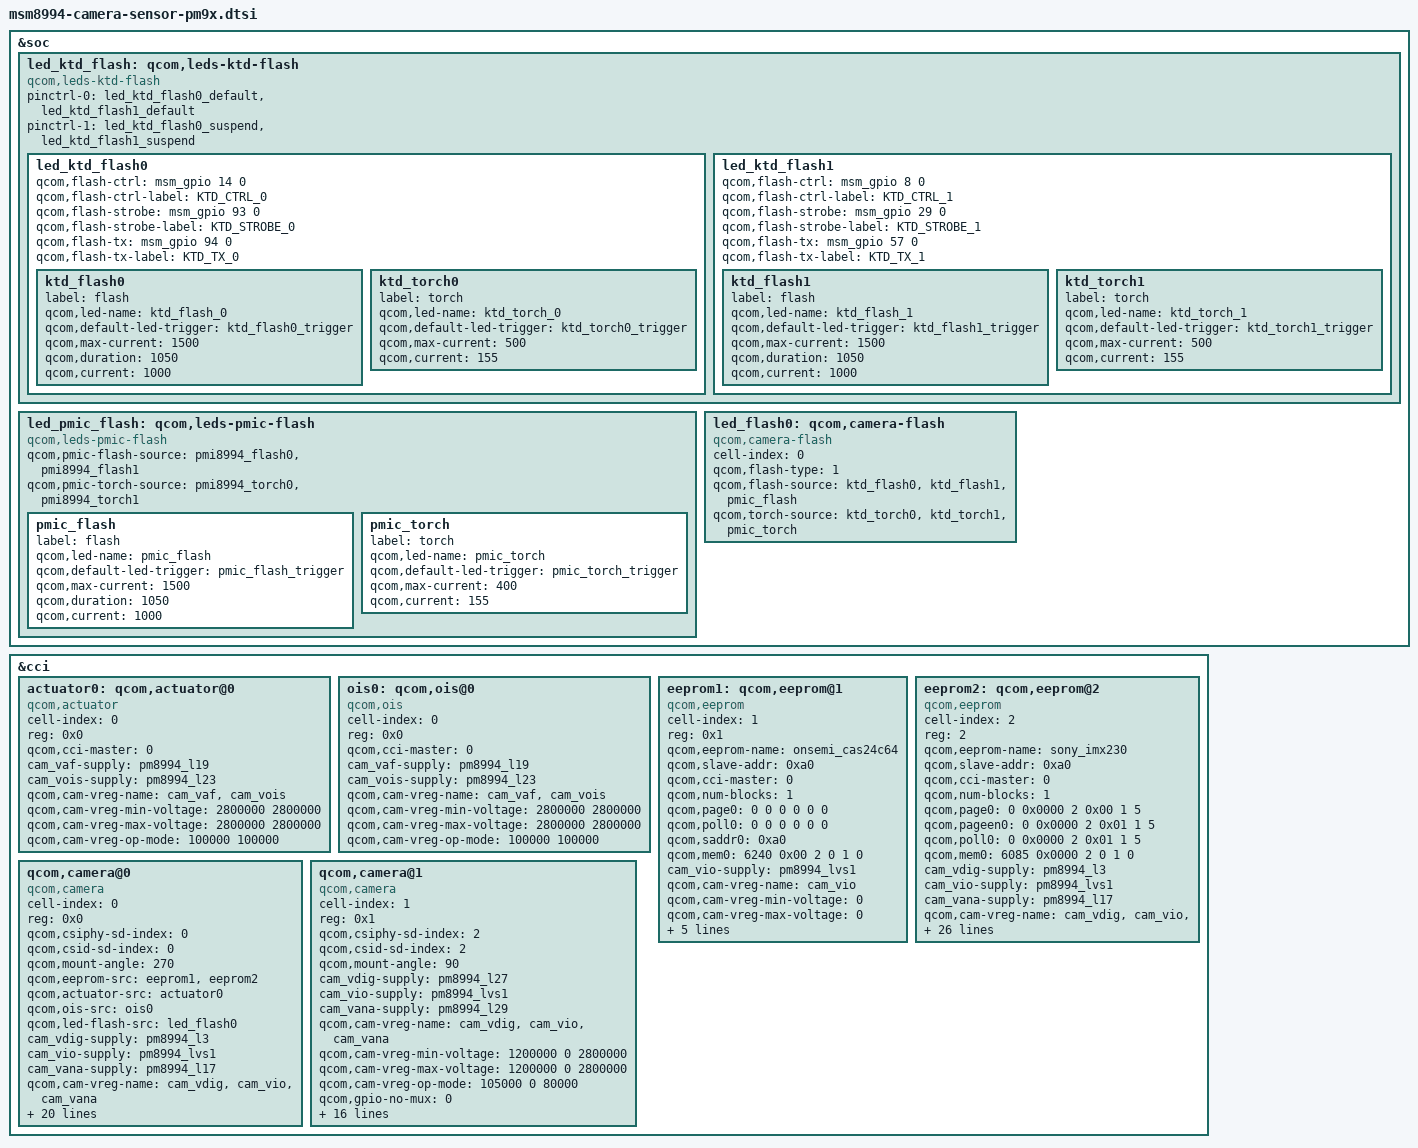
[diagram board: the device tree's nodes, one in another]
/*
 * Copyright (c) 2015, The Linux Foundation. All rights reserved.
 *
 * This program is free software; you can redistribute it and/or modify
 * it under the terms of the GNU General Public License version 2 and
 * only version 2 as published by the Free Software Foundation.
 *
 * This program is distributed in the hope that it will be useful,
 * but WITHOUT ANY WARRANTY; without even the implied warranty of
 * MERCHANTABILITY or FITNESS FOR A PARTICULAR PURPOSE.  See the
 * GNU General Public License for more details.
 */

&soc {
	led_ktd_flash: qcom,leds-ktd-flash {
		compatible = "qcom,leds-ktd-flash";
		pinctrl-names = "ktd_flash_default", "ktd_flash_suspend";
		pinctrl-0 = <&led_ktd_flash0_default &led_ktd_flash1_default>;
		pinctrl-1 = <&led_ktd_flash0_suspend &led_ktd_flash1_suspend>;

		led_ktd_flash0: led_ktd_flash0 {
			qcom,flash-ctrl = <&msm_gpio 14 0>;
			qcom,flash-ctrl-label = "KTD_CTRL_0";
			qcom,flash-strobe = <&msm_gpio 93 0>;
			qcom,flash-strobe-label = "KTD_STROBE_0";
			qcom,flash-tx = <&msm_gpio 94 0>;
			qcom,flash-tx-label = "KTD_TX_0";

			ktd_flash0: ktd_flash0 {
				label = "flash";
				qcom,led-name = "ktd_flash_0";
				qcom,default-led-trigger =
					"ktd_flash0_trigger";
				qcom,max-current = <1500>;
				qcom,duration = <1050>;
				qcom,current = <1000>;
			};

			ktd_torch0: ktd_torch0 {
				label = "torch";
				qcom,led-name = "ktd_torch_0";
				qcom,default-led-trigger =
					"ktd_torch0_trigger";
				qcom,max-current = <500>;
				qcom,current = <155>;
			};
		};

		led_ktd_flash1: led_ktd_flash1 {
			qcom,flash-ctrl = <&msm_gpio 8 0>;
			qcom,flash-ctrl-label = "KTD_CTRL_1";
			qcom,flash-strobe = <&msm_gpio 29 0>;
			qcom,flash-strobe-label = "KTD_STROBE_1";
			qcom,flash-tx = <&msm_gpio 57 0>;
			qcom,flash-tx-label = "KTD_TX_1";

			ktd_flash1: ktd_flash1 {
				label = "flash";
				qcom,led-name = "ktd_flash_1";
				qcom,default-led-trigger =
					"ktd_flash1_trigger";
				qcom,max-current = <1500>;
				qcom,duration = <1050>;
				qcom,current = <1000>;
			};

			ktd_torch1: ktd_torch1 {
				label = "torch";
				qcom,led-name = "ktd_torch_1";
				qcom,default-led-trigger =
					"ktd_torch1_trigger";
				qcom,max-current = <500>;
				qcom,current = <155>;
			};
		};
	};

	led_pmic_flash: qcom,leds-pmic-flash {
		compatible = "qcom,leds-pmic-flash";
		qcom,pmic-flash-source = <&pmi8994_flash0 &pmi8994_flash1>;
		qcom,pmic-torch-source = <&pmi8994_torch0 &pmi8994_torch1>;

		pmic_flash: pmic_flash {
			label = "flash";
			qcom,led-name = "pmic_flash";
			qcom,default-led-trigger =
				"pmic_flash_trigger";
			qcom,max-current = <1500>;
			qcom,duration = <1050>;
			qcom,current = <1000>;
		};

		pmic_torch: pmic_torch {
			label = "torch";
			qcom,led-name = "pmic_torch";
			qcom,default-led-trigger =
				"pmic_torch_trigger";
			qcom,max-current = <400>;
			qcom,current = <155>;
		};
	};

	led_flash0: qcom,camera-flash {
		cell-index = <0>;
		compatible = "qcom,camera-flash";
		qcom,flash-type = <1>;
		qcom,flash-source = <&ktd_flash0 &ktd_flash1 &pmic_flash>;
		qcom,torch-source = <&ktd_torch0 &ktd_torch1 &pmic_torch>;
	};
};

&cci {
	actuator0: qcom,actuator@0 {
		cell-index = <0>;
		reg = <0x0>;
		compatible = "qcom,actuator";
		qcom,cci-master = <0>;
		cam_vaf-supply = <&pm8994_l19>;
		cam_vois-supply = <&pm8994_l23>;
		qcom,cam-vreg-name = "cam_vaf", "cam_vois";
		qcom,cam-vreg-min-voltage = <2800000 2800000>;
		qcom,cam-vreg-max-voltage = <2800000 2800000>;
		qcom,cam-vreg-op-mode = <100000 100000>;
	};

	ois0: qcom,ois@0 {
		cell-index = <0>;
		reg = <0x0>;
		compatible = "qcom,ois";
		qcom,cci-master = <0>;
		cam_vaf-supply = <&pm8994_l19>;
		cam_vois-supply = <&pm8994_l23>;
		qcom,cam-vreg-name = "cam_vaf", "cam_vois";
		qcom,cam-vreg-min-voltage = <2800000 2800000>;
		qcom,cam-vreg-max-voltage = <2800000 2800000>;
		qcom,cam-vreg-op-mode = <100000 100000>;
	};

	eeprom1: qcom,eeprom@1 {
		cell-index = <1>;
		reg = <0x1>;
		qcom,eeprom-name = "onsemi_cas24c64";
		compatible = "qcom,eeprom";
		qcom,slave-addr = <0xa0>;
		qcom,cci-master = <0>;
		qcom,num-blocks = <1>;
		qcom,page0 = <0 0 0 0 0 0>;
		qcom,poll0 = <0 0 0 0 0 0>;
		qcom,saddr0 = <0xa0>;
		qcom,mem0 = <6240 0x00 2 0 1 0>;

		cam_vio-supply = <&pm8994_lvs1>;
		qcom,cam-vreg-name = "cam_vio";
		qcom,cam-vreg-min-voltage = <0>;
		qcom,cam-vreg-max-voltage = <0>;
		qcom,cam-vreg-op-mode = <0>;
		qcom,cam-power-seq-type = "sensor_vreg";
		qcom,cam-power-seq-val = "cam_vio";
		qcom,cam-power-seq-cfg-val = <1>;
		qcom,cam-power-seq-delay = <1>;
		status = "ok";
	};

	eeprom2: qcom,eeprom@2 {
		cell-index = <2>;
		reg = <2>;
		qcom,eeprom-name = "sony_imx230";
		compatible = "qcom,eeprom";
		qcom,slave-addr = <0xa0>;
		qcom,cci-master = <0>;
		qcom,num-blocks = <1>;
		qcom,page0 = <0 0x0000 2 0x00 1 5>;
		qcom,pageen0 = <0 0x0000 2 0x01 1 5>;
		qcom,poll0 = <0 0x0000 2 0x01 1 5>;
		qcom,mem0 = <6085 0x0000 2 0 1 0>;
		cam_vdig-supply = <&pm8994_l3>;
		cam_vio-supply = <&pm8994_lvs1>;
		cam_vana-supply = <&pm8994_l17>;
		qcom,cam-vreg-name = "cam_vdig",
			"cam_vio",
			"cam_vana";
		qcom,cam-vreg-min-voltage = <1100000 0 2500000>;
		qcom,cam-vreg-max-voltage = <1100000 0 2500000>;
		qcom,cam-vreg-op-mode = <105000 0 80000>;
		qcom,gpio-no-mux = <0>;
		pinctrl-names = "cam_default", "cam_suspend";
		pinctrl-0 = <&cam_sensor_mclk0_active &cam_sensor_rear_active>;
		pinctrl-1 = <&cam_sensor_mclk0_suspend &cam_sensor_rear_suspend>;
		gpios = <&msm_gpio 13 0>,
			<&msm_gpio 92 0>,
			<&msm_gpio 91 0>;
		qcom,gpio-reset = <1>;
		qcom,gpio-standby = <2>;
		qcom,gpio-req-tbl-num = <0 1 2>;
		qcom,gpio-req-tbl-flags = <1 0 0>;
		qcom,gpio-req-tbl-label = "CAMIF_MCLK0",
			"CAM_RESET0",
			"CAM_STANDBY0";
		qcom,cam-power-seq-type = "sensor_vreg",
			"sensor_vreg",
			"sensor_vreg",
			"sensor_gpio",
			"sensor_gpio",
			"sensor_clk";
		qcom,cam-power-seq-val = "cam_vdig",
			"cam_vana",
			"cam_vio",
			"sensor_gpio_reset",
			"sensor_gpio_standby",
			"sensor_cam_mclk";
		qcom,cam-power-seq-cfg-val = <1 1 1 1 1 24000000>;
		qcom,cam-power-seq-delay = <1 1 1 30 30 5>;
		status = "ok";
		clocks = <&clock_mmss clk_mclk0_clk_src>,
			<&clock_mmss clk_camss_mclk0_clk>;
		clock-names = "cam_src_clk", "cam_clk";
	};

	qcom,camera@0 {
		cell-index = <0>;
		compatible = "qcom,camera";
		reg = <0x0>;
		qcom,csiphy-sd-index = <0>;
		qcom,csid-sd-index = <0>;
		qcom,mount-angle = <270>;
		qcom,eeprom-src = <&eeprom1 &eeprom2>;
		qcom,actuator-src = <&actuator0>;
		qcom,ois-src = <&ois0>;
		qcom,led-flash-src = <&led_flash0>;
		cam_vdig-supply = <&pm8994_l3>;
		cam_vio-supply = <&pm8994_lvs1>;
		cam_vana-supply = <&pm8994_l17>;
		qcom,cam-vreg-name = "cam_vdig", "cam_vio", "cam_vana";
		qcom,cam-vreg-min-voltage = <1100000 0 2500000>;
		qcom,cam-vreg-max-voltage = <1100000 0 2500000>;
		qcom,cam-vreg-op-mode = <105000 0 80000>;
		qcom,gpio-no-mux = <0>;
		pinctrl-names = "cam_default", "cam_suspend";
		pinctrl-0 = <&cam_sensor_mclk0_active &cam_sensor_rear_active>;
		pinctrl-1 = <&cam_sensor_mclk0_suspend &cam_sensor_rear_suspend>;
		gpios = <&msm_gpio 13 0>,
			<&msm_gpio 92 0>,
			<&msm_gpio 91 0>;
		qcom,gpio-reset = <1>;
		qcom,gpio-standby = <2>;
		qcom,gpio-req-tbl-num = <0 1 2>;
		qcom,gpio-req-tbl-flags = <1 0 0>;
		qcom,gpio-req-tbl-label = "CAMIF_MCLK0",
			"CAM_RESET0",
			"CAM_STANDBY0";
		qcom,sensor-position = <0>;
		qcom,sensor-mode = <0>;
		qcom,cci-master = <0>;
		status = "ok";
		clocks = <&clock_mmss clk_mclk0_clk_src>,
			<&clock_mmss clk_camss_mclk0_clk>;
		clock-names = "cam_src_clk", "cam_clk";
	};

	qcom,camera@1 {
		cell-index = <1>;
		compatible = "qcom,camera";
		reg = <0x1>;
		qcom,csiphy-sd-index = <2>;
		qcom,csid-sd-index = <2>;
		qcom,mount-angle = <90>;
		cam_vdig-supply = <&pm8994_l27>;
		cam_vio-supply = <&pm8994_lvs1>;
		cam_vana-supply = <&pm8994_l29>;
		qcom,cam-vreg-name = "cam_vdig", "cam_vio", "cam_vana";
		qcom,cam-vreg-min-voltage = <1200000 0 2800000>;
		qcom,cam-vreg-max-voltage = <1200000 0 2800000>;
		qcom,cam-vreg-op-mode = <105000 0 80000>;
		qcom,gpio-no-mux = <0>;
		pinctrl-names = "cam_default", "cam_suspend";
		pinctrl-0 = <&cam_sensor_mclk2_active &cam_sensor_front_active>;
		pinctrl-1 = <&cam_sensor_mclk2_suspend &cam_sensor_front_suspend>;
		gpios = <&msm_gpio 15 0>,
			<&msm_gpio 104 0>,
			<&msm_gpio 105 0>;
		qcom,gpio-reset = <1>;
		qcom,gpio-standby = <2>;
		qcom,gpio-req-tbl-num = <0 1 2>;
		qcom,gpio-req-tbl-flags = <1 0 1>;
		qcom,gpio-req-tbl-label = "CAMIF_MCLK2",
			"CAM_RESET2",
			"CAM_STANDBY2";
		qcom,sensor-position = <1>;
		qcom,sensor-mode = <0>;
		qcom,cci-master = <1>;
		status = "ok";
		clocks = <&clock_mmss clk_mclk2_clk_src>,
			<&clock_mmss clk_camss_mclk2_clk>;
		clock-names = "cam_src_clk", "cam_clk";
	};
};
